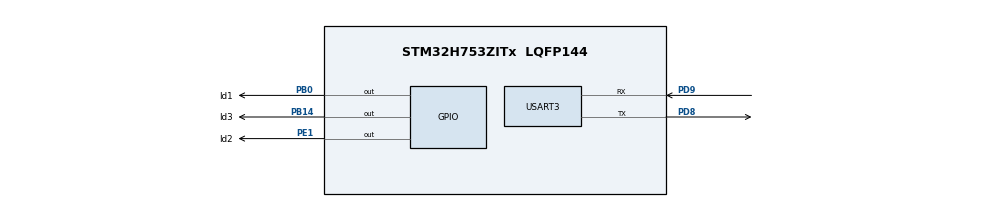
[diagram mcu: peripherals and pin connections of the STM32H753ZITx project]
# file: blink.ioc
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CORTEX_M7.CPU_DCache=Enabled
CORTEX_M7.CPU_ICache=Enabled
Mcu.Family=STM32H7
Mcu.Name=STM32H753ZITx
Mcu.Package=LQFP144
NVIC.PriorityGroup=NVIC_PRIORITYGROUP_4
PA13\ (JTMS/SWDIO).Mode=Serial_Wire
PA13\ (JTMS/SWDIO).Signal=DEBUG_JTMS-SWDIO
PA14\ (JTCK/SWCLK).Mode=Serial_Wire
PA14\ (JTCK/SWCLK).Signal=DEBUG_JTCK-SWCLK
PB0.GPIO_Label=ld1
PB0.Signal=GPIO_Output
PB14.GPIO_Label=ld3
PB14.Signal=GPIO_Output
PD8.Mode=Asynchronous
PD8.Signal=USART3_TX
PD9.Mode=Asynchronous
PD9.Signal=USART3_RX
PE1.GPIO_Label=ld2
PE1.Signal=GPIO_Output
ProjectManager.HeapSize=0x200
ProjectManager.StackSize=0x400
ProjectManager.TargetToolchain=CMake
RCC.ADCFreq_Value=129000000
RCC.APB1Freq_Value=120000000
RCC.APB2Freq_Value=120000000
RCC.APB3Freq_Value=120000000
RCC.APB4Freq_Value=120000000
RCC.CortexFreq_Value=480000000
RCC.D1PPRE=RCC_APB3_DIV2
RCC.D2PPRE1=RCC_APB1_DIV2
RCC.D2PPRE2=RCC_APB2_DIV2
RCC.D3PPRE=RCC_APB4_DIV2
RCC.DIVM1=4
RCC.DIVN1=60
RCC.HCLKFreq_Value=240000000
RCC.HPRE=RCC_HCLK_DIV2
RCC.PLLFRACN=0
RCC.PWR_Regulator_Voltage_Scale=PWR_REGULATOR_VOLTAGE_SCALE0
RCC.SYSCLKFreq_VALUE=480000000
RCC.SYSCLKSource=RCC_SYSCLKSOURCE_PLLCLK
RCC.USBFreq_Value=480000000
USART3.VirtualMode-Asynchronous=VM_ASYNC
VP_MEMORYMAP_VS_MEMORYMAP.Mode=CurAppReg
board=NUCLEO-H753ZI

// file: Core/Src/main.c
/* USER CODE BEGIN Header */
/**
  ******************************************************************************
  * @file           : main.c
  * @brief          : Main program body
  ******************************************************************************
  * @attention
  *
  * Copyright (c) 2026 STMicroelectronics.
  * All rights reserved.
  *
  * This software is licensed under terms that can be found in the LICENSE file
  * in the root directory of this software component.
  * If no LICENSE file comes with this software, it is provided AS-IS.
  *
  ******************************************************************************
  */
/* USER CODE END Header */
#include "main.h"

/* USER CODE BEGIN Includes */
#include "app_rt.h"
#include "bench.h"
#include "board.h"
/* USER CODE END Includes */

UART_HandleTypeDef huart3;

void SystemClock_Config(void);
static void MX_GPIO_Init(void);
static void MX_USART3_UART_Init(void);

int main(void)
{

  /* Enable the CPU Cache */

  /* Enable I-Cache---------------------------------------------------------*/
  SCB_EnableICache();

  /* Enable D-Cache---------------------------------------------------------*/
  SCB_EnableDCache();

  /* MCU Configuration--------------------------------------------------------*/

  /* Reset of all peripherals, Initializes the Flash interface and the Systick. */
  HAL_Init();

  /* Configure the system clock */
  SystemClock_Config();

  /* Initialize all configured peripherals */
  MX_GPIO_Init();
  MX_USART3_UART_Init();
  /* USER CODE BEGIN 2 */
  board_init();                       /* DWT cycle counter */
#ifdef EMG_RT
  app_rt_run();                       /* route B: real-time loop, samples from the PC (never returns) */
#else
  bench_run(SystemCoreClock);         /* firmware v2 timing, results on the virtual COM port */
#endif
  /* USER CODE END 2 */

  /* Infinite loop */
  while (1)
  {

    /* USER CODE BEGIN 3 */
    HAL_GPIO_TogglePin(ld1_GPIO_Port, ld1_Pin);   /* blinking = the bench has finished */
    HAL_Delay(500);
  }
  /* USER CODE END 3 */
}

void SystemClock_Config(void)
{
  RCC_OscInitTypeDef RCC_OscInitStruct = {0};
  RCC_ClkInitTypeDef RCC_ClkInitStruct = {0};

  /** Supply configuration update enable
  */
  HAL_PWREx_ConfigSupply(PWR_LDO_SUPPLY);

  /** Configure the main internal regulator output voltage
  */
  __HAL_PWR_VOLTAGESCALING_CONFIG(PWR_REGULATOR_VOLTAGE_SCALE0);

  while(!__HAL_PWR_GET_FLAG(PWR_FLAG_VOSRDY)) {}

  /** Initializes the RCC Oscillators according to the specified parameters
  * in the RCC_OscInitTypeDef structure.
  */
  RCC_OscInitStruct.OscillatorType = RCC_OSCILLATORTYPE_HSI;
  RCC_OscInitStruct.HSIState = RCC_HSI_DIV1;
  RCC_OscInitStruct.HSICalibrationValue = RCC_HSICALIBRATION_DEFAULT;
  RCC_OscInitStruct.PLL.PLLState = RCC_PLL_ON;
  RCC_OscInitStruct.PLL.PLLSource = RCC_PLLSOURCE_HSI;
  RCC_OscInitStruct.PLL.PLLM = 4;
  RCC_OscInitStruct.PLL.PLLN = 60;
  RCC_OscInitStruct.PLL.PLLP = 2;
  RCC_OscInitStruct.PLL.PLLQ = 2;
  RCC_OscInitStruct.PLL.PLLR = 2;
  RCC_OscInitStruct.PLL.PLLRGE = RCC_PLL1VCIRANGE_3;
  RCC_OscInitStruct.PLL.PLLVCOSEL = RCC_PLL1VCOWIDE;
  RCC_OscInitStruct.PLL.PLLFRACN = 0;
  if (HAL_RCC_OscConfig(&RCC_OscInitStruct) != HAL_OK)
  {
    Error_Handler();
  }

  /** Initializes the CPU, AHB and APB buses clocks
  */
  RCC_ClkInitStruct.ClockType = RCC_CLOCKTYPE_HCLK|RCC_CLOCKTYPE_SYSCLK
                              |RCC_CLOCKTYPE_PCLK1|RCC_CLOCKTYPE_PCLK2
                              |RCC_CLOCKTYPE_D3PCLK1|RCC_CLOCKTYPE_D1PCLK1;
  RCC_ClkInitStruct.SYSCLKSource = RCC_SYSCLKSOURCE_PLLCLK;
  RCC_ClkInitStruct.SYSCLKDivider = RCC_SYSCLK_DIV1;
  RCC_ClkInitStruct.AHBCLKDivider = RCC_HCLK_DIV2;
  RCC_ClkInitStruct.APB3CLKDivider = RCC_APB3_DIV2;
  RCC_ClkInitStruct.APB1CLKDivider = RCC_APB1_DIV2;
  RCC_ClkInitStruct.APB2CLKDivider = RCC_APB2_DIV2;
  RCC_ClkInitStruct.APB4CLKDivider = RCC_APB4_DIV2;

  if (HAL_RCC_ClockConfig(&RCC_ClkInitStruct, FLASH_LATENCY_4) != HAL_OK)
  {
    Error_Handler();
  }
}

static void MX_USART3_UART_Init(void)
{

  huart3.Instance = USART3;
  huart3.Init.BaudRate = 115200;
  huart3.Init.WordLength = UART_WORDLENGTH_8B;
  huart3.Init.StopBits = UART_STOPBITS_1;
  huart3.Init.Parity = UART_PARITY_NONE;
  huart3.Init.Mode = UART_MODE_TX_RX;
  huart3.Init.HwFlowCtl = UART_HWCONTROL_NONE;
  huart3.Init.OverSampling = UART_OVERSAMPLING_16;
  huart3.Init.OneBitSampling = UART_ONE_BIT_SAMPLE_DISABLE;
  huart3.Init.ClockPrescaler = UART_PRESCALER_DIV1;
  huart3.AdvancedInit.AdvFeatureInit = UART_ADVFEATURE_NO_INIT;
  if (HAL_UART_Init(&huart3) != HAL_OK)
  {
    Error_Handler();
  }
  if (HAL_UARTEx_SetTxFifoThreshold(&huart3, UART_TXFIFO_THRESHOLD_1_8) != HAL_OK)
  {
    Error_Handler();
  }
  if (HAL_UARTEx_SetRxFifoThreshold(&huart3, UART_RXFIFO_THRESHOLD_1_8) != HAL_OK)
  {
    Error_Handler();
  }
  if (HAL_UARTEx_DisableFifoMode(&huart3) != HAL_OK)
  {
    Error_Handler();
  }

}

static void MX_GPIO_Init(void)
{
  GPIO_InitTypeDef GPIO_InitStruct = {0};

  /* GPIO Ports Clock Enable */
  __HAL_RCC_GPIOB_CLK_ENABLE();
  __HAL_RCC_GPIOD_CLK_ENABLE();
  __HAL_RCC_GPIOA_CLK_ENABLE();
  __HAL_RCC_GPIOE_CLK_ENABLE();

  /*Configure GPIO pin Output Level */
  HAL_GPIO_WritePin(GPIOB, ld1_Pin|ld3_Pin, GPIO_PIN_RESET);

  /*Configure GPIO pin Output Level */
  HAL_GPIO_WritePin(ld2_GPIO_Port, ld2_Pin, GPIO_PIN_RESET);

  /*Configure GPIO pins : ld1_Pin ld3_Pin */
  GPIO_InitStruct.Pin = ld1_Pin|ld3_Pin;
  GPIO_InitStruct.Mode = GPIO_MODE_OUTPUT_PP;
  GPIO_InitStruct.Pull = GPIO_NOPULL;
  GPIO_InitStruct.Speed = GPIO_SPEED_FREQ_LOW;
  HAL_GPIO_Init(GPIOB, &GPIO_InitStruct);

  /*Configure GPIO pin : ld2_Pin */
  GPIO_InitStruct.Pin = ld2_Pin;
  GPIO_InitStruct.Mode = GPIO_MODE_OUTPUT_PP;
  GPIO_InitStruct.Pull = GPIO_NOPULL;
  GPIO_InitStruct.Speed = GPIO_SPEED_FREQ_LOW;
  HAL_GPIO_Init(ld2_GPIO_Port, &GPIO_InitStruct);

}

void Error_Handler(void)
{
  __disable_irq();
  while (1)
  {
  }
}
